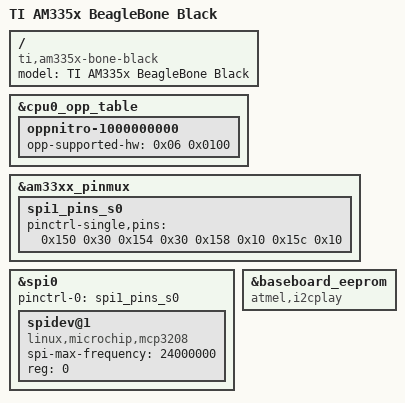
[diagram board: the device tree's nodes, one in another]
// SPDX-License-Identifier: GPL-2.0-only
/*
 * Copyright (C) 2012 Texas Instruments Incorporated - http://www.ti.com/
 */
/dts-v1/;

#include "am33xx.dtsi"
#include "am335x-bone-common.dtsi"
#include "am335x-boneblack-common.dtsi"

/ {
	model = "TI AM335x BeagleBone Black";
	compatible = "ti,am335x-bone-black", "ti,am335x-bone", "ti,am33xx";
};

&cpu0_opp_table {
	/*
	 * All PG 2.0 silicon may not support 1GHz but some of the early
	 * BeagleBone Blacks have PG 2.0 silicon which is guaranteed
	 * to support 1GHz OPP so enable it for PG 2.0 on this board.
	 */
	oppnitro-1000000000 {
		opp-supported-hw = <0x06 0x0100>;
	};
};


&am33xx_pinmux {
	spi1_pins_s0: spi1_pins_s0 {
		pinctrl-single,pins = <0x150 0x30 0x154 0x30 0x158 0x10 0x15c 0x10>;
	};
};

&spi0 {
	status = "okay";
	pinctrl-names = "default";
	pinctrl-0 = <&spi1_pins_s0>;

	spidev@1 {
		spi-max-frequency = <24000000>;
		reg = <0>;
		compatible = "linux,microchip,mcp3208";
	};
};

&baseboard_eeprom {
	compatible = "atmel,i2cplay";
};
